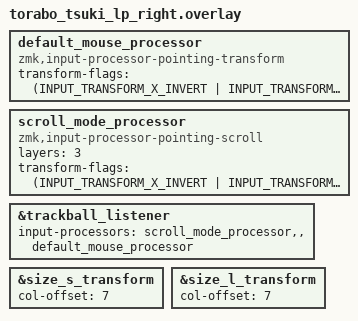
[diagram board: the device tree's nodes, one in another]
#include "torabo_tsuki_lp.dtsi"
#include <input/processors.dtsi>
#include <dt-bindings/zmk/input_transform.h>

default_mouse_processor: default_mouse_processor {
    compatible = "zmk,input-processor-pointing-transform";
    transform-flags = <(INPUT_TRANSFORM_X_INVERT | INPUT_TRANSFORM_Y_INVERT)>;
};

scroll_mode_processor: scroll_mode_processor {
    compatible = "zmk,input-processor-pointing-scroll";
    layers = <3>;
    transform-flags = <(INPUT_TRANSFORM_X_INVERT | INPUT_TRANSFORM_Y_INVERT)>;
    // scale = <150>; // スクロール速度を調整したい場合はコメントを外して数値を変更
};

&trackball_listener {
    input-processors = <&scroll_mode_processor, &default_mouse_processor>;
};

&size_s_transform {
    col-offset = <7>;
};

// &size_m_transform {
//     col-offset = <7>;
// };

&size_l_transform {
    col-offset = <7>;
};
